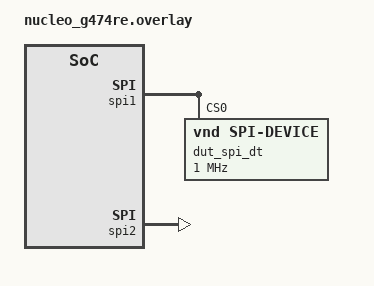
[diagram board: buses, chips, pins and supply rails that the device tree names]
/*
 * SPDX-License-Identifier: Apache-2.0
 * Copyright (c) 2026 Bhavin Umatiya
 */

&spi1 {
	status = "okay";
	dut_spi_dt: test-spi-dev@0 {
		compatible = "vnd,spi-device";
		reg = <0>;
		spi-max-frequency = <1000000>;
	};
};

dut_spis: &spi2 {
	status = "okay";
	peripheral-cs = <0>;
};
